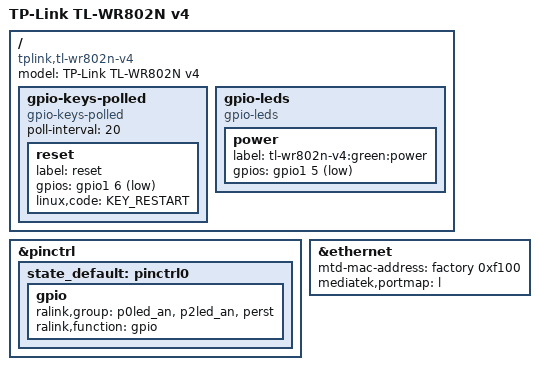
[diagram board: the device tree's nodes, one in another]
/dts-v1/;

#include "TL-WR84XN.dtsi"

#include <dt-bindings/gpio/gpio.h>
#include <dt-bindings/input/input.h>

/ {
	compatible = "tplink,tl-wr802n-v4", "mediatek,mt7628an-soc";
	model = "TP-Link TL-WR802N v4";

	gpio-keys-polled {
		compatible = "gpio-keys-polled";
		#address-cells = <1>;
		#size-cells = <0>;
		poll-interval = <20>;

		reset {
			label = "reset";
			gpios = <&gpio1 6 GPIO_ACTIVE_LOW>;
			linux,code = <KEY_RESTART>;
		};
	};

	gpio-leds {
		compatible = "gpio-leds";

		power {
			label = "tl-wr802n-v4:green:power";
			gpios = <&gpio1 5 GPIO_ACTIVE_LOW>;
		};
	};
};

&pinctrl {
	state_default: pinctrl0 {
		gpio {
			ralink,group = "p0led_an", "p2led_an", "perst";
			ralink,function = "gpio";
		};
	};
};

&ethernet {
	mtd-mac-address = <&factory 0xf100>;
	mediatek,portmap = "l";
};
